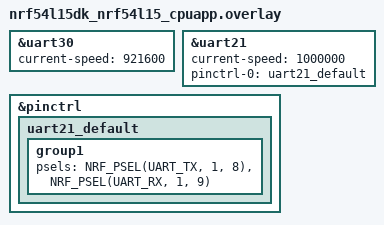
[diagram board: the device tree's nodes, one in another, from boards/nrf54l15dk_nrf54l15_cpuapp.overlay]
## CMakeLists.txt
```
cmake_minimum_required(VERSION 3.20.0)

find_package(Zephyr REQUIRED HINTS $ENV{ZEPHYR_BASE})
project(cs_multi_initiator)

target_sources(app PRIVATE
	src/main.c
	src/cs_config.c
	src/beacon.c
	src/pairing.c
	src/cs_ranging.c
	src/if.c
	src/manager.c
)

target_include_directories(app PRIVATE src)
```

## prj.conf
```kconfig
# ── Base Bluetooth ──
CONFIG_BT=y
CONFIG_BT_CENTRAL=y
CONFIG_BT_DEVICE_NAME="CS Initiator"
# Must be >= MAX_BEACONS (beacon.h)
CONFIG_BT_MAX_CONN=5
# CRITICAL: even in non-bonding (BT_BONDABLE=n), each encrypted connection
# occupies a slot of the bt_keys pool (key_pool[CONFIG_BT_MAX_PAIRED]) for the
# whole session — the session LTK lives there. Zephyr default = 1: from the 2nd
# beacon on, bt_conn_set_security -> bt_keys_get_addr -> pool full (the single
# slot belongs to the connected beacon, so "in use", impossible to purge) ->
# -ENOMEM (-12) in a loop. parnav_cs had this line.
CONFIG_BT_MAX_PAIRED=5

# ── Security (BT_SECURITY_L2, Just Works) ──
CONFIG_BT_SMP=y
# No bonding: without CONFIG_BT_SETTINGS the keys do not survive a reboot, and
# stale RAM bonds break re-securing (err 2 PIN_OR_KEY_MISSING) and saturate the
# key pool (-ENOMEM). CS security only requires an encrypted link: per-session
# pairing, no storage.
CONFIG_BT_BONDABLE=n

# ── NCS scan (UUID filter + auto connect) ──
CONFIG_BT_SCAN=y
CONFIG_BT_SCAN_FILTER_ENABLE=y
CONFIG_BT_SCAN_UUID_CNT=1

# ── GATT client + service discovery (RAS) ──
CONFIG_BT_GATT_CLIENT=y
CONFIG_BT_GATT_DM=y

# ── Channel Sounding ──
CONFIG_BT_CHANNEL_SOUNDING=y
# One CS context per connection at the controller level: without it (default =
# 1), the CS setup of the 2nd reflector fails for lack of resources
CONFIG_BT_CTLR_SDC_CS_COUNT=5
# Duration RESERVED by the SDC in the timeline for each CS event (default =
# 5000 us). Must be >= max_subevent_len (4500 us in cs_config.c), otherwise
# HCI 0x12 at Set Procedure Parameters.
# ⚠ This is a scheduling RESERVATION: 16000 inflated the footprint of each CS
# slot -> the SDC could not find a placement below ~50-60 ms interval (0x0c)
# and deferred the 1st subevent (~700 ms startup). 5000 = 4500 + margin, sticks
# to the real airtime (~10 ms of useful measurement).
CONFIG_BT_CTLR_SDC_CS_EVENT_LEN_DEFAULT=5000

# ── Compaction of the central scheduling (THE ~700 ms bottleneck) ──
# When BT_CTLR_CHANNEL_SOUNDING=y, the SDC by DEFAULT spaces the ACL anchors of
# the central connections by 90000 us (90 ms!) to fit a CS event behind each
# ACL. With 2 links at 60/77.5 ms interval, this 90 ms grid is untenable: the
# SDC defers the 1st CS subevent until it finds a slot (~10-13 connection
# events) and refuses short intervals. We resize it to our real footprints:
#   ACL (3750) + CS event (5000) + margin ≈ 15000 us per link.
# 2 links x 15 ms = 30 ms -> connection interval 24 (30 ms).
# ⚠ TESTED 10000/interval 16: systematic 0x3 abort on both beacons — 1250 us of
#   margin per slot is insufficient (ACL retransmissions, slippage). 15000
#   validated: startup 340 ms, fetch 130-180 ms, 0 abort. Possible intermediate
#   step to validate: 12500 + interval 20 (25 ms).
CONFIG_BT_CTLR_SDC_CENTRAL_ACL_EVENT_SPACING_DEFAULT=15000
# ACL reservation per link: 7500 us by default, brought down to 3750. The event
# extension (CONFIG_BT_CTLR_SDC_CONN_EVENT_EXTEND_DEFAULT=y by default)
# opportunistically lengthens the event when data remains (RAS fetch) and there
# is no conflict: GATT throughput does not collapse.
CONFIG_BT_CTLR_SDC_MAX_CONN_EVENT_LEN_DEFAULT=3750
# One host reassembly buffer per active CS connection (key = conn_handle, freed
# only at disconnection or at the end of a procedure). Default = 1: a residual
# buffer from an aborted procedure on one link can starve the other link. Align
# on MAX_BEACONS (beacon.h) — CRITICAL in free-running (max_procedure_count=0):
# the N links produce procedures in parallel permanently. 5 = CONFIG_BT_MAX_CONN
# (covers all profiles).
CONFIG_BT_CHANNEL_SOUNDING_REASSEMBLY_BUFFER_CNT=5
# Lets CS and ACL use different PHYs (present in the validated single-beacon
# sample)
CONFIG_BT_TRANSMIT_POWER_CONTROL=y

# ── Ranging Service: client (Ranging REQuestor) ──
CONFIG_BT_RAS=y
CONFIG_BT_RAS_RREQ=y

# ── MTU/ACL: fast transfer of the ranging data ──
CONFIG_BT_L2CAP_TX_MTU=247
CONFIG_BT_BUF_ACL_TX_SIZE=251
CONFIG_BT_BUF_ACL_RX_SIZE=251
CONFIG_BT_ATT_PREPARE_COUNT=2

# ── Floats (atan2f, regression) ──
CONFIG_FPU=y
# Several threads use the FPU (ranging in main + display_thread which logs
# floats): without FPU_SHARING the FPU registers are corrupted on a context
# switch
CONFIG_FPU_SHARING=y
# Formatting of the %f in LOG_INF (otherwise corrupted output)
CONFIG_CBPRINTF_FP_SUPPORT=y

# ── Misc ──
CONFIG_DK_LIBRARY=y
CONFIG_SERIAL=y
CONFIG_LOG=y
CONFIG_MAIN_STACK_SIZE=4096
CONFIG_SYSTEM_WORKQUEUE_STACK_SIZE=4096

# ── RTT: enlarged buffer so the boot logs are not lost before the JLink
#    terminal attaches (default = 1 KB, skip mode) ──
CONFIG_USE_SEGGER_RTT=y
CONFIG_LOG_BACKEND_RTT=y
CONFIG_SEGGER_RTT_BUFFER_SIZE_UP=4096
CONFIG_UART_INTERRUPT_DRIVEN=y
```

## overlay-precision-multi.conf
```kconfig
# CONF_DOCKING_PRECISION / CONF_INDOOR_PRECISION profiles with CS_NUM_REFLECTORS=2
# Subevent 8000 us -> CS reservation 8500; grid:
#   SPACING >= ACL 3750 + CS 8500 + guard >= 3000  -> 20000
#   interval = 2 x 20000 = 40 ms (CS_CONN_INTERVAL_UNITS=32 in the profile)
CONFIG_BT_CTLR_SDC_CS_EVENT_LEN_DEFAULT=8500
CONFIG_BT_CTLR_SDC_CENTRAL_ACL_EVENT_SPACING_DEFAULT=20000
# On the REFLECTORS side: mirror CS_EVENT_LEN_DEFAULT=8500.
```

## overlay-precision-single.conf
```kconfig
# CONF_DOCKING_PRECISION / CONF_INDOOR_PRECISION profiles with CS_NUM_REFLECTORS=1
CONFIG_BT_CTLR_SDC_CS_EVENT_LEN_DEFAULT=8500
# A single central link: SPACING has no effect, left at the default.
# On the REFLECTOR side: mirror CS_EVENT_LEN_DEFAULT=8500.
```

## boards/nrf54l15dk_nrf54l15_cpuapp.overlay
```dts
/* ── Initiator UARTs ────────────────────────────────────────────────────────
 * DK mapping (J-Link OB):
 *   uart20  P1.04/P1.05 -> VCOM (Serial Port 1): Zephyr console/logs
 *   uart30  P0.00/P0.01 -> VCOM (Serial Port 0): OUR data+commands channel
 *   uart21  P1.08/P1.09 -> extension header (NO VCOM): drone link
 * if.c selects uart30 (bench PC) or uart21 (drone-embedded) via
 * IF_UART_ON_VCOM in if.c. */

/* 1 Mbaud on the data channel: the continuous IQ dump (IQL/IQP) drops from
 * ~30-60 ms to ~4-7 ms per procedure. Both UARTs set to the same rate to cover
 * if.c's two targets (uart30 = bench-PC VCOM; uart21 = drone link). NB: at
 * 1 Mbaud the DK's J-Link OB may truncate depending on its firmware version;
 * if the IQ lines are corrupt on the VCOM, drop uart30 back to 921600. */
&uart30 {
    status = "okay";
    current-speed = <921600>;
};

&uart21 {
    status = "okay";
    current-speed = <1000000>;
    pinctrl-0 = <&uart21_default>;
    pinctrl-names = "default";
};

&pinctrl {
    uart21_default: uart21_default {
        group1 {
            psels = <NRF_PSEL(UART_TX, 1, 8)>, <NRF_PSEL(UART_RX, 1, 9)>;
        };
    };
};
```

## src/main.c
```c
/*
 * Copyright (c) 2024 Nordic Semiconductor ASA
 * SPDX-License-Identifier: LicenseRef-Nordic-5-Clause
 */

#include <zephyr/kernel.h>
#include <zephyr/bluetooth/bluetooth.h>
#include <zephyr/bluetooth/conn.h>
#include <bluetooth/scan.h>
#include "beacon.h"
#include "pairing.h"
#include "cs_ranging.h"
#include "if.h"
#include "manager.h"
#include "cs_config.h"

#include <dk_buttons_and_leds.h>

#include <zephyr/logging/log.h>
LOG_MODULE_REGISTER(app_main, LOG_LEVEL_INF);

/* Ranging Service UUID 0x185B — advertised by the reflector firmware */
static struct bt_uuid_16 ranging_svc_uuid = BT_UUID_INIT_16(0x185B);
#define BT_UUID_RANGING_SERVICE ((struct bt_uuid *)&ranging_svc_uuid)

#define CON_STATUS_LED DK_LED1

/* Declared in pairing.c */
extern void security_changed_cb(struct bt_conn *conn, bt_security_t level,
				enum bt_security_err err);

/* ── Connection callbacks ────────────────────────────────────────────────── */

static void connected_cb(struct bt_conn *conn, uint8_t err)
{
	char addr[BT_ADDR_LE_STR_LEN];

	bt_addr_le_to_str(bt_conn_get_dst(conn), addr, sizeof(addr));
	LOG_INF("Connected: %s (err 0x%02X)", addr, err);

	if (err) {
		/* No unref here: the application has not taken a reference yet,
		 * the scan module manages its own. */
		return;
	}

	/* Reject duplicate connection to already-connected beacon */
	const bt_addr_le_t *addr_le = bt_conn_get_dst(conn);

	/* Whitelist manager: rejects any address off the list when the
	 * whitelist is active (WL:ON). Always OK when disabled. */
	if (!manager_addr_allowed(addr_le)) {
		LOG_WRN("Connection rejected (not whitelisted): %s", addr);
		bt_conn_disconnect(conn, BT_HCI_ERR_REMOTE_USER_TERM_CONN);
		return;
	}

	k_mutex_lock(&beacons_mutex, K_FOREVER);
	for (int i = 0; i < MAX_BEACONS; i++) {
		if (beacons[i].active && beacons[i].conn != NULL &&
		    bt_addr_le_cmp(bt_conn_get_dst(beacons[i].conn), addr_le) == 0) {
			k_mutex_unlock(&beacons_mutex);
			LOG_WRN("Duplicate connection rejected");
			bt_conn_disconnect(conn, BT_HCI_ERR_REMOTE_USER_TERM_CONN);
			return;
		}
	}
	k_mutex_unlock(&beacons_mutex);

	struct bt_conn *ref = bt_conn_ref(conn);

	if (k_msgq_put(&new_conn_queue, &ref, K_NO_WAIT) != 0) {
		LOG_ERR("Queue full, disconnecting");
		bt_conn_unref(ref);
		bt_conn_disconnect(conn, BT_HCI_ERR_REMOTE_USER_TERM_CONN);
		return;
	}

	dk_set_led_on(CON_STATUS_LED);
}

static void disconnected_cb(struct bt_conn *conn, uint8_t reason)
{
	char addr[BT_ADDR_LE_STR_LEN];

	bt_addr_le_to_str(bt_conn_get_dst(conn), addr, sizeof(addr));
	LOG_INF("Disconnected: %s (reason 0x%02X)", addr, reason);

	/* Release-once: the unref is done only if THIS call freed the slot.
	 * Avoids the double-unref (refcount underflow) racing with the pairing
	 * thread's error path. */
	if (free_beacon(conn)) {
		bt_conn_unref(conn);
	}

	dk_set_led_off(CON_STATUS_LED);
}

static bool le_param_req(struct bt_conn *conn, struct bt_le_conn_param *param)
{
	return false;
}

BT_CONN_CB_DEFINE(conn_cb) = {
	.connected      = connected_cb,
	.disconnected   = disconnected_cb,
	.le_param_req   = le_param_req,
	.security_changed = security_changed_cb,
};

/* ── Scan ────────────────────────────────────────────────────────────────── */

static void scan_filter_match(struct bt_scan_device_info *device_info,
			      struct bt_scan_filter_match *filter_match, bool connectable)
{
	char addr[BT_ADDR_LE_STR_LEN];

	bt_addr_le_to_str(device_info->recv_info->addr, addr, sizeof(addr));
	LOG_INF("Found beacon: %s", addr);
}

static void scan_connecting_error(struct bt_scan_device_info *device_info)
{
	LOG_WRN("Connection attempt failed");
}

static void scan_connecting(struct bt_scan_device_info *device_info, struct bt_conn *conn)
{
	LOG_INF("Connecting...");
}

BT_SCAN_CB_INIT(scan_cb, scan_filter_match, NULL, scan_connecting_error, scan_connecting);

static int scan_init(void)
{
	int err;
	/* Initial connection parameters = cs_cp_active (single source in
	 * cs_config.h/.c). No static init possible from a variable: we point
	 * the scan directly at the global struct. */
	struct bt_scan_init_param param = {
		.scan_param = NULL,
		.conn_param = &cs_cp_active,
		.connect_if_match = 1,
	};

	bt_scan_init(&param);
	bt_scan_cb_register(&scan_cb);

	err = bt_scan_filter_add(BT_SCAN_FILTER_TYPE_UUID, BT_UUID_RANGING_SERVICE);
	if (err) {
		LOG_ERR("Filter add failed (err %d)", err);
		return err;
	}

	err = bt_scan_filter_enable(BT_SCAN_UUID_FILTER, false);
	if (err) {
		LOG_ERR("Filter enable failed (err %d)", err);
		return err;
	}

	return 0;
}

/* ── 1 Hz display ────────────────────────────────────────────────────────── */

/* 2048: the cbprintf packaging of the %f in LOG_INF happens in the caller
 * context — 512 bytes overflowed the stack (random hard fault). */
#define DISPLAY_STACK_SIZE 2048
#define DISPLAY_PRIORITY   7
K_THREAD_STACK_DEFINE(display_stack, DISPLAY_STACK_SIZE);
static struct k_thread display_thread_data;

static void display_thread(void *p1, void *p2, void *p3)
{
	char addr_str[BT_ADDR_LE_STR_LEN];

	while (true) {
		k_sleep(K_MSEC(1000));

		k_mutex_lock(&beacons_mutex, K_FOREVER);
		int n = 0;

		for (int i = 0; i < MAX_BEACONS; i++) {
			if (!beacons[i].active) {
				continue;
			}
			n++;
			bt_addr_le_to_str(&beacons[i].addr, addr_str, sizeof(addr_str));
			LOG_INF("[%d] %s  %s", i, addr_str,
				beacons[i].cs_ready ? "ranging" : "setup");
		}

		if (n == 0) {
			LOG_INF("No beacons connected");
		}

		k_mutex_unlock(&beacons_mutex);
	}
}

/* ── Main ────────────────────────────────────────────────────────────────── */

int main(void)
{
	int err;

	LOG_INF("Starting multi-beacon initiator");

	dk_leds_init();

	if (if_initialisation()) {
		LOG_ERR("UART init failed");
	}

	/* Application manager: UART commands (IQON/IQOFF, whitelist, chmap),
	 * connection filtering by whitelist, channel-map hot-swap staging. */
	manager_init();
	if_set_line_cb(manager_uart_line);

	err = bt_enable(NULL);
	if (err) {
		LOG_ERR("Bluetooth init failed (err %d)", err);
		return 0;
	}

	err = scan_init();
	if (err) {
		LOG_ERR("Scan init failed (err %d)", err);
		return 0;
	}

	k_thread_create(&pairing_thread_data, pairing_stack, PAIRING_STACK_SIZE,
			(k_thread_entry_t)pairing_n_bluetooth, NULL, NULL, NULL,
			PAIRING_PRIORITY, 0, K_NO_WAIT);

	k_thread_create(&display_thread_data, display_stack, DISPLAY_STACK_SIZE,
			display_thread, NULL, NULL, NULL,
			DISPLAY_PRIORITY, 0, K_NO_WAIT);

	/* ── Blocking init: do not continue until the MAX_BEACONS reflectors
	 *    are connected and secured ──────────────────────────────────── */
	LOG_INF("Waiting for %d reflectors...", MAX_BEACONS);
	err = pairing_wait_all_connected(K_FOREVER);
	if (err) {
		LOG_ERR("Wait for reflectors failed (err %d)", err);
		return 0;
	}
	LOG_INF("All %d reflectors connected — starting application", MAX_BEACONS);

	/* ── CONTINUOUS MEASUREMENT (free-running) ───────────────────────────────
	 * Each beacon's CS procedures are armed ONCE (max_procedure_count = 0):
	 * the controller then repeats them every procedure_interval without a new
	 * LL handshake — the ~495 ms startup (≈ 11 x connection interval) is paid
	 * only at arming, never again per measurement. The old one-shot pipeline
	 * paid this startup on EVERY measurement (3-beacon cycle ≈ 1485 ms); here
	 * the loop only collects the pairs (local steps + peer RAS) as they come:
	 * cycle ≈ procedure period (~180 ms in drone N=3).
	 * NOTE: no bt_conn_ref during the measurement (a disconnect mid-cycle is
	 * unprotected) — OK on the bench, to harden for production. */
	cs_ranging_init();

	bool armed[MAX_BEACONS] = { false };

	while (true) {
		bool enable_failed = false;
		bool any_collected = false;
		int64_t t_cycle = k_uptime_get();

		/* Simple round-robin over all beacons (the scheduler was removed:
		 * in free-running each link measures continuously, the order has
		 * no effect on the rate). */
		for (int i = 0; i < MAX_BEACONS; i++) {
			bool ready;

			k_mutex_lock(&beacons_mutex, K_FOREVER);
			ready = beacons[i].active && beacons[i].cs_ready &&
				beacons[i].conn != NULL;
			k_mutex_unlock(&beacons_mutex);

			if (!ready) {
				/* Disconnected: the controller has stopped its
				 * procedures, we will re-arm on return. */
				armed[i] = false;
				continue;
			}

			/* Not armed yet (startup, reconnection, or failure on
			 * the previous round): arm and move on — the first
			 * measurement arrives after the LL startup, while the
			 * loop collects the other beacons. */
			if (!armed[i]) {
				armed[i] = (cs_enable_beacon(i) == 0);
				enable_failed |= !armed[i];
				continue;
			}

			/* Collect the next paired measurement + timestamped IQ
			 * dump (IQL/IQP). No distance: computed off-board
			 * (Python) from the IQ lines. */
			bool rearmed = true;
			int rc = cs_collect_beacon(i, &rearmed);

			any_collected = true;
			if (!rearmed) {
				armed[i] = false;
				enable_failed = true;
			}
			if (rc != 0) {
				LOG_WRN("Beacon[%d] ranging failed", i);
			}
		}

		LOG_INF("cycle: %lld ms", k_uptime_get() - t_cycle);

		/* Backoff if nothing was collected this round (all disconnected
		 * or just armed): avoids a busy spin. In nominal operation the
		 * loop is paced by the collection semaphores (cs_collect_beacon). */
		if (enable_failed || !any_collected) {
			k_sleep(K_MSEC(50));
		}
	}

	return 0;
}
```

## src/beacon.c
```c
#include "beacon.h"

#include <zephyr/logging/log.h>
LOG_MODULE_DECLARE(app_main, LOG_LEVEL_INF);

struct beacon_state beacons[MAX_BEACONS];
K_MUTEX_DEFINE(beacons_mutex);
K_MSGQ_DEFINE(new_conn_queue, sizeof(struct bt_conn *), MAX_BEACONS, sizeof(void *));

struct beacon_state *find_beacon(struct bt_conn *conn)
{
	for (int i = 0; i < MAX_BEACONS; i++) {
		if (beacons[i].active && beacons[i].conn == conn) {
			return &beacons[i];
		}
	}
	return NULL;
}

struct beacon_state *alloc_beacon(struct bt_conn *conn)
{
	k_mutex_lock(&beacons_mutex, K_FOREVER);
	for (int i = 0; i < MAX_BEACONS; i++) {
		if (!beacons[i].active) {
			beacons[i].conn     = conn;
			beacons[i].active   = true;
			beacons[i].cs_ready = false;
			bt_addr_le_copy(&beacons[i].addr, bt_conn_get_dst(conn));
			k_mutex_unlock(&beacons_mutex);
			return &beacons[i];
		}
	}
	k_mutex_unlock(&beacons_mutex);
	return NULL;
}

bool free_beacon(struct bt_conn *conn)
{
	bool released = false;

	if (conn == NULL) {
		return false;
	}

	k_mutex_lock(&beacons_mutex, K_FOREVER);
	for (int i = 0; i < MAX_BEACONS; i++) {
		if (beacons[i].conn == conn) {
			beacons[i].active        = false;
			beacons[i].conn          = NULL;
			beacons[i].cs_ready      = false;
			released = true;
			break;
		}
	}
	k_mutex_unlock(&beacons_mutex);

	return released;
}

void decalage(void)
{
	k_mutex_lock(&beacons_mutex, K_FOREVER);
	for (int left = 0; left < MAX_BEACONS; left++) {
		if (beacons[left].active) {
			continue;
		}
		/* free slot found: look for the next active one to the right */
		for (int right = left + 1; right < MAX_BEACONS; right++) {
			if (beacons[right].active) {
				beacons[left]         = beacons[right];
				beacons[right].active = false;
				beacons[right].conn   = NULL;
				break;
			}
		}
	}
	k_mutex_unlock(&beacons_mutex);
}
```

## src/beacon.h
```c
#ifndef BEACON_H
#define BEACON_H

#include <zephyr/kernel.h>
#include <zephyr/bluetooth/conn.h>

#include "cs_config.h"

/* Sized by the application profile (cs_config.h) */
#define MAX_BEACONS CS_MAX_BEACONS

struct beacon_state {
	struct bt_conn *conn;
	bt_addr_le_t   addr;
	bool           active;
	/* Channel Sounding */
	bool           cs_ready;     /* CS setup done, ranging possible */
	uint8_t        cs_config_id; /* CS config id returned by the controller */
};

extern struct beacon_state beacons[MAX_BEACONS];
extern struct k_mutex      beacons_mutex;
extern struct k_msgq       new_conn_queue;

struct beacon_state *find_beacon(struct bt_conn *conn);
struct beacon_state *alloc_beacon(struct bt_conn *conn);
/* Frees the slot associated with conn. Returns true ONLY for the caller that
 * actually freed the slot: it is the one that must call bt_conn_unref.
 * Guarantees exactly one unref even if disconnected_cb and the pairing error
 * path run concurrently. */
bool                 free_beacon(struct bt_conn *conn);
void                 decalage(void);

#endif /* BEACON_H */
```

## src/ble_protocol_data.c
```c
#include "ble_protocol_data.h"
#include "if.h"
#include <string.h>
#include <zephyr/logging/log.h>
#define MAX_NUM_IQ_SAMPLES 148

LOG_MODULE_DECLARE(app_main, LOG_LEVEL_INF);

#define MAX_PACKET_SIZE (2 + 15 * MAX_NUM_IQ_SAMPLES + 2)  /* 15 octets/sample : beacon_idx + channel + antenna + 4xIQ + float */

static uint8_t buffer[MAX_PACKET_SIZE];

void ble_protocol_data_send_batch(const struct iq_sample_packet *samples,
                                  uint16_t count) {
    if (count == 0) {
        return;
    }

    /* Avec la config CS validée (mode 2+1, chmap repetition 5), une
     * procédure peut produire plus de MAX_NUM_IQ_SAMPLES échantillons :
     * on découpe en plusieurs trames au lieu de jeter le lot entier
     * (l'ancien code faisait `return` silencieusement). */
    while (count > MAX_NUM_IQ_SAMPLES) {
        ble_protocol_data_send_batch(samples, MAX_NUM_IQ_SAMPLES);
        samples += MAX_NUM_IQ_SAMPLES;
        count -= MAX_NUM_IQ_SAMPLES;
    }

    uint16_t offset = 0;

    // Header: 'R~'
    const uint8_t header[] = {0x52, 0x7E};
    memcpy(&buffer[offset], header, sizeof(header));
    offset += sizeof(header);

    // IQ Sample Payload
    for (uint16_t i = 0; i < count; i++) {
        const struct iq_sample_packet *s = &samples[i];

        memcpy(&buffer[offset], &s->beacon_idx, sizeof(s->beacon_idx));
        offset += sizeof(s->beacon_idx);
        memcpy(&buffer[offset], &s->channel, sizeof(s->channel));
        offset += sizeof(s->channel);
        memcpy(&buffer[offset], &s->antenna_index, sizeof(s->antenna_index));
        offset += sizeof(s->antenna_index);

        memcpy(&buffer[offset], &s->local_i, sizeof(int16_t));
        offset += sizeof(int16_t);
        memcpy(&buffer[offset], &s->local_q, sizeof(int16_t));
        offset += sizeof(int16_t);
        memcpy(&buffer[offset], &s->peer_i, sizeof(int16_t));
        offset += sizeof(int16_t);
        memcpy(&buffer[offset], &s->peer_q, sizeof(int16_t));
        offset += sizeof(int16_t);

        // New: Serialize phase_distance_m
        memcpy(&buffer[offset], &s->phase_distance_m, sizeof(float));
        offset += sizeof(float);
    }

    // Footer: '~E'
    const uint8_t footer[] = {0x7E, 0x45};
    memcpy(&buffer[offset], footer, sizeof(footer));
    offset += sizeof(footer);

    LOG_INF("Serialisation done, buffer length = %d", offset);
    if_send(buffer, offset);

}
```

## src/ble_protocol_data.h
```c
#ifndef BLE_PROTOCOL_DATA_H_
#define BLE_PROTOCOL_DATA_H_

#include <stdint.h>

// #define MAX_NUM_IQ_SAMPLES (256 * CONFIG_BT_RAS_MAX_ANTENNA_PATHS)

struct iq_sample_packet {
	uint8_t beacon_idx;   /* identifie le réflecteur source de la mesure */
	uint8_t channel;
	uint8_t antenna_index;
	int16_t local_i;
	int16_t local_q;
	int16_t peer_i;
	int16_t peer_q;
	float phase_distance_m;
};

void ble_protocol_data_send_batch(const struct iq_sample_packet *samples, uint16_t count);

#endif /* BLE_PROTOCOL_DATA_H_ */
```

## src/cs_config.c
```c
#include "cs_config.h"

/* ── CONSISTENCY GUARDS prj.conf <-> profile (see cs_config.h) ─────────────
 * Refuse compilation if the SDC timeline reservations do not cover the selected
 * profile — this is exactly the class of errors that produced the historical
 * 700 ms startup and 0x3 aborts. */
BUILD_ASSERT(CONFIG_BT_CTLR_SDC_CS_EVENT_LEN_DEFAULT >= CS_SUBEVENT_LEN_US,
	     "CS_EVENT_LEN_DEFAULT < max_subevent_len: Procedure Params rejected (0x12). "
	     "Adapt the prj.conf overlay to the profile.");
BUILD_ASSERT(CS_NUM_BEACONS >= 1 && CS_NUM_BEACONS <= 5,
	     "CS_NUM_BEACONS must be between 1 and 5.");
BUILD_ASSERT(CONFIG_BT_MAX_CONN >= CS_NUM_BEACONS,
	     "CONFIG_BT_MAX_CONN < CS_NUM_BEACONS (prj.conf).");
BUILD_ASSERT(CONFIG_BT_CTLR_SDC_CS_COUNT >= CS_NUM_BEACONS,
	     "CONFIG_BT_CTLR_SDC_CS_COUNT < CS_NUM_BEACONS: not enough concurrent "
	     "CS procedures for the pipeline (prj.conf).");
#if CS_MAX_BEACONS > 1
BUILD_ASSERT(CONFIG_BT_CTLR_SDC_CENTRAL_ACL_EVENT_SPACING_DEFAULT >=
	     CONFIG_BT_CTLR_SDC_MAX_CONN_EVENT_LEN_DEFAULT +
	     CONFIG_BT_CTLR_SDC_CS_EVENT_LEN_DEFAULT + 3000,
	     "SPACING too small for ACL + CS event + 3 ms guard: structural 0x3 "
	     "aborts guaranteed (20 ms/10000 measurement failure).");
BUILD_ASSERT(CS_CONN_INTERVAL_UNITS * 1250 >=
	     CS_MAX_BEACONS * CONFIG_BT_CTLR_SDC_CENTRAL_ACL_EVENT_SPACING_DEFAULT,
	     "Connection interval < N_links x SPACING: the grid does not fit "
	     "(Procedure Enable 0x0C or deferred startup).");
#endif

struct bt_le_cs_set_default_settings_param cs_settings = {
    .enable_initiator_role     = true,
    .enable_reflector_role     = false,
    .cs_sync_antenna_selection = BT_LE_CS_ANTENNA_SELECTION_OPT_ONE,
    .max_tx_power              = CS_MAX_TX_POWER, /* profile: max for range,
                                                   * reduced in docking (anti-
                                                   * saturation < a few meters) */
};

struct bt_le_cs_create_config_params cs_create_config = {
    .id                     = 0,
    .mode                   = CS_MODE, /* profile: PBR + RTT (drone, ambiguity resolution beyond the non-ambiguous range) or pure PBR (short-range precision) */
    .min_main_mode_steps    = 2,
    .max_main_mode_steps    = CS_MAIN_STEPS_MAX, /* more steps/subevent = channels packed tighter (precision profiles) vs short subevents (drone profiles) */
    .main_mode_repetition   = 1,
    .mode_0_steps           = CS_MODE0_STEPS,    /* 3 in precision: better frequency-offset estimation */
    .role                   = BT_CONN_LE_CS_ROLE_INITIATOR,
    .rtt_type               = CS_RTT_TYPE, /* 32-bit sounding (drone): fine timestamping + NADM; AA_ONLY (pure PBR) */
    .cs_sync_phy            = CS_SYNC_PHY, /* 2M_2BT only refines the CS_SYNC (RTT), not the PBR phase */
    .channel_map_repetition = CS_CHMAP_REPETITION, /* 2 in docking N<=2: each channel sounded 2x (slow and near target, ODS note) */
    .channel_selection_type = CS_CHSEL_TYPE, /* 3C+X in fast drone: time-frequency decorrelation (ODS note) */
    .ch3c_shape             = CS_CH3C_SHAPE,
    .ch3c_jump              = 2,
    .cs_enhancements_1      = 0,
};

struct bt_le_cs_set_procedure_parameters_param cs_proc_params = {
    .config_id              = 0, /* updated at runtime in do_set_procedure_params() */
    .max_procedure_len      = CS_PROC_LEN_UNITS, /* x0.625 ms. Short window = easy placement (drone); wide for ~72 channels (precision) */
    /* Per-link sampling period = interval x connection interval (unit:
     * connection events). Drone N=3: 4 x 45 ms = 180 ms/beacon. */
    .min_procedure_interval = 4,
    .max_procedure_interval = 4,
    /* 0 = FREE-RUNNING: the controller repeats the procedures every
     * procedure_interval until disable. The LL handshake (~11 events x
     * interval ≈ 495 ms) is paid ONLY ONCE at arming, never again per
     * measurement — it was what capped the rate in one-shot
     * (max_procedure_count=1: 3-beacon cycle ≈ 1485 ms observed). */
    .max_procedure_count    = 0,
    .min_subevent_len       = CS_SUBEVENT_LEN_US,
    .max_subevent_len       = CS_SUBEVENT_LEN_US, /* ⚠ coupled to CONFIG_BT_CTLR_SDC_CS_EVENT_LEN_DEFAULT (BUILD_ASSERT above) */
    .tone_antenna_config_selection = BT_LE_CS_TONE_ANTENNA_CONFIGURATION_A1_B1,
    .phy                    = BT_LE_CS_PROCEDURE_PHY_2M,
    .tx_power_delta         = 0x80,
    .preferred_peer_antenna = 1,
    .snr_control_initiator  = BT_LE_CS_SNR_CONTROL_NOT_USED,
    .snr_control_reflector  = BT_LE_CS_SNR_CONTROL_NOT_USED,
};

struct bt_le_conn_param cs_cp_active = {
    /* FIXED interval (min == max). CS startup ≈ ~11 events x interval
     * (LL_CS_REQ/RSP/IND + SDC margin: the NUMBER of events is not
     * configurable, only their DURATION is). In multi: interval =
     * CS_MAX_BEACONS x SPACING (deterministic grid, cf. BUILD_ASSERT).
     * In single: floor = ACL + CS event + margin, SPACING does not apply
     * (a single central connection).
     * VALIDATED multi-drone 24/15000: startup 340 ms, 0 abort.
     * FAILURE 16/10000: 1250 us guard too tight → structural 0x3 abort. */
    .interval_min = CS_CONN_INTERVAL_UNITS,
    .interval_max = CS_CONN_INTERVAL_UNITS,
    .latency      = 0,
    .timeout      = 3200,
};
```

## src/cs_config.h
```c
#ifndef CS_CONFIG_H_
#define CS_CONFIG_H_

/*io pin trigger par une interruption pour chaque cs ranging et envoyer a la sentiboard pour avoir un timestamp */

#include <zephyr/bluetooth/bluetooth.h>
#include <zephyr/bluetooth/conn.h>
#include <zephyr/bluetooth/cs.h>

/* ═══════════════════════════════════════════════════════════════════════════
 * 1) FAMILLE APPLICATIVE — décommenter EXACTEMENT UNE.
 * 2) CS_NUM_BEACONS — nombre de réflecteurs (1 à 5). TOUT le timing et le
 *    dimensionnement en découlent automatiquement (intervalle = N × créneau,
 *    buffers, scheduler) ; garde-fous BUILD_ASSERT dans cs_config.c.
 *
 * Overlays prj.conf par famille (réservations SDC, indépendantes de N) :
 *   DRONE_FAST_OUTDOOR : aucun (prj.conf de base : CS_EVENT 5000/SPACING 15000)
 *   BOAT_DOCKING / DRONE_INDOOR, N>=2 : overlay-precision-multi.conf
 *   BOAT_DOCKING / DRONE_INDOOR, N==1 : overlay-precision-single.conf
 * Rappel : reflasher aussi les réflecteurs si CS_EVENT_LEN change de famille.
 * Référence des paramètres : doc_optimised_parameters.ods (renvois Vol 6 H).
 * ═══════════════════════════════════════════════════════════════════════════ */
//#define CONF_DRONE_FAST_OUTDOOR   /*drone extérieur rapide */
#define CONF_BOAT_DOCKING /*   accostage bateau, précision courte portée */
//- #define CONF_DRONE_INDOOR    /* drone lent intérieur, multipath dense */

#define CS_NUM_BEACONS 2          /* 1..5 */

/* Mode de récupération des ranging data pair : 1 = RAS temps réel (fetch ~0,
 * pas de rétention), 0 = on-demand (fallback validé). Voir itération 3. */
#define CS_RAS_REALTIME 1

/* ─────────────────────────────────────────────────────────────────────────
 * FAMILLE : DRONE EXTÉRIEUR RAPIDE
 * Priorité : cadence + robustesse au mouvement. Peu de canaux (airtime et
 * data minimaux), créneau de 15 ms/lien, RTT sounding (levée d'ambiguïté
 * fiable au-delà de 50 m). NOTE capacités SDC : 3C/X, 2M_2BT, sounding et
 * NADM documentés dans l'ODS ne sont PAS supportés par le SoftDevice
 * Controller (Create Config 0x11 constaté) — voir le bloc CS_RTT_TYPE.
 * ───────────────────────────────────────────────────────────────────────── */
#if defined(CONF_DRONE_FAST_OUTDOOR)
#define CS_CHANNEL_THINNING     3     /* ~24 canaux, non-ambigu PBR 50 m */
#define CS_SUBEVENT_LEN_US      4500
#define CS_PROC_LEN_UNITS       40    /* 25 ms : fenêtre courte, placement facile */
#define CS_MODE0_STEPS          2
#define CS_MAIN_STEPS_MAX       6
#define CS_MODE                 BT_CONN_LE_CS_MAIN_MODE_2_SUB_MODE_1 /*tester sans submode
/* ⚠ CAPACITÉS SDC (table nrfxlib, vérifiée sur cible — Create Config 0x11
 * sinon) : sounding sequence, CSA #3C, 2M_2BT et NADM NON SUPPORTÉS par le
 * SoftDevice Controller. Le levier de datation RTT DISPONIBLE est la
 * random payload (32/64/96/128 bits, supportée) : corrélation affinée vs
 * AA-only, même rôle que la sounding d'après la spec (§2, Vol 6 Part H).
 * Fallback validé banc : BT_CONN_LE_CS_RTT_TYPE_AA_ONLY. */
#define CS_RTT_TYPE             BT_CONN_LE_CS_RTT_TYPE_32_BIT_RANDOM
#define CS_SYNC_PHY             BT_CONN_LE_CS_SYNC_2M_PHY      /* 2M_2BT non supporté SDC */
#define CS_CHSEL_TYPE           BT_CONN_LE_CS_CHSEL_TYPE_3B    /* #3C non supporté SDC */
#define CS_CH3C_SHAPE           BT_CONN_LE_CS_CH3C_SHAPE_HAT   /* sans effet en 3B */
#define CS_CHMAP_REPETITION     1
#define CS_MAX_TX_POWER         BT_HCI_OP_LE_CS_MAX_MAX_TX_POWER
#define CS_SPACING_UNITS        12    /* 15 ms/lien = ACL 3750 + CS 5000 + marge */
#define CS_SINGLE_FLOOR_UNITS   12
/* RAM : à 4-5 beacons, buffers réduits (24 canaux → ~30 steps réels). */
#define CS_MAX_STEPS_PER_PROC   (CS_NUM_BEACONS >= 4 ? 48 : 64)
#define CS_SCHED_DEFAULT_REPEAT 1

/* ─────────────────────────────────────────────────────────────────────────
 * FAMILLE : ACCOSTAGE BATEAU (précision, < 30 m, dynamique lente)
 * Tous les canaux = résolution max ; TX 0 dBm (anti-saturation proche) ;
 * cible lente et proche → channel_map_repetition 2 quand la RAM le permet
 * (N<=2, cf. note ODS), sinon moyennage par le scheduler (2 mesures/round).
 * PBR pur (non-ambigu 150 m >> enveloppe) → pas de RTT, chsel 3B (statique).
 * ⚠ N>=4 : thinning 2 imposé (75 m non-ambigu, RAM ~÷2 par beacon).
 * ───────────────────────────────────────────────────────────────────────── */
#elif defined(CONF_BOAT_DOCKING)
#define CS_CHANNEL_THINNING     (CS_NUM_BEACONS >= 3 ? 2 : 1)
#define CS_SUBEVENT_LEN_US      8000
#define CS_PROC_LEN_UNITS       100   /* 62,5 ms : ~72 canaux à écouler */
#define CS_MODE0_STEPS          3
#define CS_MAIN_STEPS_MAX       10
#define CS_MODE                 BT_CONN_LE_CS_MAIN_MODE_2_NO_SUB_MODE
#define CS_RTT_TYPE             BT_CONN_LE_CS_RTT_TYPE_AA_ONLY /* sans objet en PBR pur */
#define CS_SYNC_PHY             BT_CONN_LE_CS_SYNC_2M_PHY
#define CS_CHSEL_TYPE           BT_CONN_LE_CS_CHSEL_TYPE_3B
#define CS_CH3C_SHAPE           BT_CONN_LE_CS_CH3C_SHAPE_HAT   /* inutilisé en 3B */
#define CS_CHMAP_REPETITION     (CS_NUM_BEACONS <= 2 ? 2 : 1)
/* Puissance TX max (EIRP) de TOUTES les transmissions CS. PLAFOND : le
 * contrôleur prend le niveau matériel supporté le plus proche <= cette valeur.
 * Plage HCI -127..+20 dBm ; nRF54L15 : max réel +8 dBm (au-delà = plafonné).
 * BT_HCI_OP_LE_CS_MAX_MAX_TX_POWER (=20) = "prends le maximum matériel".
 * ⚠ Baisser la TX ne réduit PAS le multipath (direct et réflexions atténués du
 *   même rapport) : le 0 dBm ci-dessous est de l'anti-saturation courte portée
 *   (< qq m, un signal trop fort déforme la phase), pas un filtre multipath.
 *   À distance / en extérieur, MONTER la TX pour le SNR.
 * Paliers indicatifs (dBm) :
 *      0    accostage serré < ~3 m (anti-saturation)      <-- valeur actuelle
 *     +4    intérieur / quelques mètres
 *     +8    extérieur, portée max nRF54L15
 *   BT_HCI_OP_LE_CS_MAX_MAX_TX_POWER   laisse le contrôleur prendre son max */
#define CS_MAX_TX_POWER         8    /* dBm */
#define CS_SPACING_UNITS        16    /* 20 ms/lien = ACL 3750 + CS 8500 + marge */
#define CS_SINGLE_FLOOR_UNITS   16
#define CS_MAX_STEPS_PER_PROC   (CS_NUM_BEACONS <= 2 ? 176 : \
                                 (CS_NUM_BEACONS == 3 ? 96 : 64))
#define CS_SCHED_DEFAULT_REPEAT 2

/* ─────────────────────────────────────────────────────────────────────────
 * FAMILLE : DRONE LENT INTÉRIEUR (multipath dense)
 * La diversité fréquentielle est LE remède au multipath : tous les canaux,
 * mode-0 renforcé, TX max (budget NLOS). Cible lente → 3B suffit ; le
 * lissage vient du scheduler (2 mesures/round) + pondération γ côté Python.
 * ⚠ N>=4 : thinning 2 imposé (RAM), à éviter si le multipath est sévère.
 * ───────────────────────────────────────────────────────────────────────── */
#elif defined(CONF_DRONE_INDOOR)
#define CS_CHANNEL_THINNING     (CS_NUM_BEACONS >= 4 ? 2 : 1)
#define CS_SUBEVENT_LEN_US      8000
#define CS_PROC_LEN_UNITS       100
#define CS_MODE0_STEPS          3
#define CS_MAIN_STEPS_MAX       10
#define CS_MODE                 BT_CONN_LE_CS_MAIN_MODE_2_NO_SUB_MODE
#define CS_RTT_TYPE             BT_CONN_LE_CS_RTT_TYPE_AA_ONLY
#define CS_SYNC_PHY             BT_CONN_LE_CS_SYNC_2M_PHY
#define CS_CHSEL_TYPE           BT_CONN_LE_CS_CHSEL_TYPE_3B
#define CS_CH3C_SHAPE           BT_CONN_LE_CS_CH3C_SHAPE_HAT
#define CS_CHMAP_REPETITION     1
#define CS_MAX_TX_POWER         BT_HCI_OP_LE_CS_MAX_MAX_TX_POWER
#define CS_SPACING_UNITS        16
#define CS_SINGLE_FLOOR_UNITS   16
#define CS_MAX_STEPS_PER_PROC   (CS_NUM_BEACONS >= 4 ? 64 : 96)
#define CS_SCHED_DEFAULT_REPEAT 2

#else
#error "cs_config.h : sélectionner exactement une famille CONF_*"
#endif

/* ── Dérivés communs (ne pas éditer) ────────────────────────────────────────
 * Intervalle de connexion : N==1 → plancher single (le quadrillage SPACING ne
 * s'applique qu'entre connexions centrales) ; N>=2 → N × créneau, le SDC
 * espace les ancres ACL de SPACING (déterministe, sans collision).
 * Startup ≈ 11 × intervalle (LL_CS_REQ/RSP/IND + marge SDC, incompressible
 * en nombre), payé UNE FOIS à l'armement en free-running
 *#define CS_CHANNEL_THINNING  (CS_NUM_BEACONS >= 3 ? 2 : 1) (max_procedure_count = 0). La cadence en régime établi vaut ensuite
 * procedure_interval × intervalle de connexion par beacon (∝ N). */
#define CS_MAX_BEACONS          CS_NUM_BEACONS
#define CS_CONN_INTERVAL_UNITS  (CS_NUM_BEACONS == 1 ? CS_SINGLE_FLOOR_UNITS \
                                 : CS_NUM_BEACONS * CS_SPACING_UNITS)
#define CS_ACL_DESYNC_STEP      0  /* précession inutile avec le quadrillage ;
                                    * fallback 6 si aborts 0x3 figés */

extern struct bt_le_cs_set_default_settings_param     cs_settings;
extern struct bt_le_cs_create_config_params           cs_create_config;
extern struct bt_le_cs_set_procedure_parameters_param cs_proc_params;
extern struct bt_le_conn_param                        cs_cp_active;
/* cs_cp_standby SUPPRIMÉ : vestige round-robin actif/veille. Perspective
 * N>=4 (note ODS sur .id/config par réflecteur) : parquer en latency les
 * beacons hors du round courant — non implémenté. */

#endif /* CS_CONFIG_H_ */
```

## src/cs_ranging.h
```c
#ifndef CS_RANGING_H
#define CS_RANGING_H

#include <zephyr/kernel.h>
#include "beacon.h"

/* Full Channel Sounding setup for a freshly secured (L2) beacon: RAS
 * discovery, capabilities, default settings, CS config, CS security, procedure
 * parameters. BLOCKING (internal semaphores).
 * Call from the pairing thread, sequentially.
 * Returns 0 if the beacon is ready for ranging. */
int cs_setup_beacon(struct beacon_state *beacon);

/* Init of the per-beacon measurement states. Call once before the loop. */
void cs_ranging_init(void);

/* FREE-RUNNING (max_procedure_count = 0: the controller repeats the procedures
 * every procedure_interval, the ~495 ms LL handshake is paid only at arming):
 *  - cs_enable_beacon(i)  : ARMS beacon i's procedures, ONCE (and after a
 *                           reconnection). Returns 0 if accepted.
 *  - cs_collect_beacon(i) : waits for the next paired measurement (local steps
 *                           + peer ranging data of the same counter) and emits
 *                           the timestamped IQ dump (IQL/IQP). Returns 0 if a
 *                           measurement was emitted, < 0 otherwise. *rearmed
 *                           goes false if the beacon must be re-armed (on-demand
 *                           path only). NO distance computation (done off-board).
 * Collection consumes no airtime: the N links' procedures run in the
 * background, the per-beacon rate = procedure_interval x connection interval
 * (measurements not collected in time: overwritten, not accumulated). */
/* Timestamped IQ dump to the data UART (ON by default, disabled by the UART
 * command IQOFF / re-enabled by IQON, line format documented in GUIDE.md). */
extern bool cs_iq_dump;

int cs_enable_beacon(int i);
int cs_collect_beacon(int i, bool *rearmed);

#endif /* CS_RANGING_H */
```

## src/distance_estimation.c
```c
#include <zephyr/logging/log.h>
LOG_MODULE_DECLARE(app_main, LOG_LEVEL_INF);

#include <zephyr/bluetooth/cs.h>
#include <bluetooth/services/ras.h>
#include <zephyr/bluetooth/hci_types.h>
#include "ble_protocol_data.h"
#include "beacon.h"
#include <math.h>

#define MAX_NUM_IQ_SAMPLES (256 * CONFIG_BT_RAS_MAX_ANTENNA_PATHS)
#define DISTANCE_FILTER_LEN 8

#define CS_FREQUENCY_MHZ(ch)   (2402u + 1u * (ch))
#define SPEED_OF_LIGHT_M_PER_S 299792458.0f
#define PI                     3.14159265358979323846f

struct iq_sample_and_channel {
	bool failed;
	uint8_t channel;
	uint8_t antenna_permutation;
	struct bt_le_cs_iq_sample local_iq_sample;
	struct bt_le_cs_iq_sample peer_iq_sample;
};

static struct iq_sample_and_channel iq_sample_channel_data[MAX_NUM_IQ_SAMPLES];

/* Un filtre glissant PAR beacon : un filtre global mélangerait les
 * distances mesurées vers des réflecteurs différents. */
static float distance_filter[MAX_BEACONS][DISTANCE_FILTER_LEN];
static uint8_t distance_filter_idx[MAX_BEACONS];
static uint8_t distance_filter_count[MAX_BEACONS];

static float filtered_distance(uint8_t beacon_idx, float new_sample)
{
	if (beacon_idx >= MAX_BEACONS) {
		return -1.0f;
	}
	if (new_sample <= 0.0f || new_sample > 50.0f) {
		return -1.0f;
	}
	distance_filter[beacon_idx][distance_filter_idx[beacon_idx]] = new_sample;
	distance_filter_idx[beacon_idx] =
		(distance_filter_idx[beacon_idx] + 1) % DISTANCE_FILTER_LEN;
	if (distance_filter_count[beacon_idx] < DISTANCE_FILTER_LEN) {
		distance_filter_count[beacon_idx]++;
	}
	float sum = 0.0f;
	for (uint8_t i = 0; i < distance_filter_count[beacon_idx]; i++) {
		sum += distance_filter[beacon_idx][i];
	}
	return sum / distance_filter_count[beacon_idx];
}

struct processing_context {
	uint16_t iq_sample_channel_data_index;
	uint8_t n_ap;
	enum bt_conn_le_cs_role role;
};

static void process_tone_info_data(struct processing_context *context,
			      struct bt_hci_le_cs_step_data_tone_info local_tone_info[],
			      struct bt_hci_le_cs_step_data_tone_info peer_tone_info[],
			      uint8_t channel, uint8_t antenna_permutation_index)
{
	for (uint8_t i = 0; i < (context->n_ap + 1); i++) {
		if (local_tone_info[i].extension_indicator != BT_HCI_LE_CS_NOT_TONE_EXT_SLOT ||
		    peer_tone_info[i].extension_indicator != BT_HCI_LE_CS_NOT_TONE_EXT_SLOT) {
			continue;
		}

		if (context->iq_sample_channel_data_index >= MAX_NUM_IQ_SAMPLES) {
			LOG_WRN("Too many IQ samples");
			return;
		}

		struct iq_sample_and_channel *entry =
			&iq_sample_channel_data[context->iq_sample_channel_data_index];

		entry->channel = channel;
		entry->antenna_permutation = antenna_permutation_index;
		entry->local_iq_sample =
			bt_le_cs_parse_pct(local_tone_info[i].phase_correction_term);
		entry->peer_iq_sample =
			bt_le_cs_parse_pct(peer_tone_info[i].phase_correction_term);

		entry->failed =
			(local_tone_info[i].quality_indicator == BT_HCI_LE_CS_TONE_QUALITY_LOW ||
			 local_tone_info[i].quality_indicator == BT_HCI_LE_CS_TONE_QUALITY_UNAVAILABLE ||
			 peer_tone_info[i].quality_indicator == BT_HCI_LE_CS_TONE_QUALITY_LOW ||
			 peer_tone_info[i].quality_indicator == BT_HCI_LE_CS_TONE_QUALITY_UNAVAILABLE);

		context->iq_sample_channel_data_index++;
	}
}

static bool process_step_data(struct bt_le_cs_subevent_step *local_step,
			      struct bt_le_cs_subevent_step *peer_step, void *user_data)
{
	struct processing_context *context = (struct processing_context *)user_data;

	if (local_step->mode == BT_HCI_OP_LE_CS_MAIN_MODE_2 ||
	    local_step->mode == BT_HCI_OP_LE_CS_MAIN_MODE_3) {

		struct bt_hci_le_cs_step_data_mode_2 *local_step_data =
			(struct bt_hci_le_cs_step_data_mode_2 *)local_step->data;
		struct bt_hci_le_cs_step_data_mode_2 *peer_step_data =
			(struct bt_hci_le_cs_step_data_mode_2 *)peer_step->data;

		process_tone_info_data(context, local_step_data->tone_info,
				       peer_step_data->tone_info, local_step->channel,
				       local_step_data->antenna_permutation_index);
	}

	return true;
}

static void calc_complex_product(int32_t z_a_real, int32_t z_a_imag, int32_t z_b_real,
				 int32_t z_b_imag, int32_t *z_out_real, int32_t *z_out_imag)
{
	*z_out_real = z_a_real * z_b_real - z_a_imag * z_b_imag;
	*z_out_imag = z_a_real * z_b_imag + z_a_imag * z_b_real;
}

static float linear_regression(float *x_values, float *y_values, uint16_t n_samples)
{
	if (n_samples == 0) {
		return 0.0f;
	}

	float y_mean = 0.0f;
	float x_mean = 0.0f;

	for (uint16_t i = 0; i < n_samples; i++) {
		y_mean += (y_values[i] - y_mean) / (i + 1);
		x_mean += (x_values[i] - x_mean) / (i + 1);
	}

	float b_est_upper = 0.0f;
	float b_est_lower = 0.0f;

	for (uint16_t i = 0; i < n_samples; i++) {
		b_est_upper += (x_values[i] - x_mean) * (y_values[i] - y_mean);
		b_est_lower += (x_values[i] - x_mean) * (x_values[i] - x_mean);
	}

	return b_est_upper / b_est_lower;
}

static void bubblesort_2(float *array1, float *array2, uint16_t len)
{
	for (uint16_t i = 0; i < len - 1; i++) {
		for (uint16_t j = 0; j < len - i - 1; j++) {
			if (array1[j] > array1[j + 1]) {
				float temp1 = array1[j];
				array1[j] = array1[j + 1];
				array1[j + 1] = temp1;

				float temp2 = array2[j];
				array2[j] = array2[j + 1];
				array2[j + 1] = temp2;
			}
		}
	}
}

static float estimate_distance_using_phase_slope(struct iq_sample_and_channel *data, uint16_t len)
{
	int32_t combined_i, combined_q;
	uint16_t num_angles = 0;
	static float theta[MAX_NUM_IQ_SAMPLES];
	static float frequencies[MAX_NUM_IQ_SAMPLES];

	for (uint16_t i = 0; i < len; i++) {
		if (!data[i].failed) {
			calc_complex_product(data[i].local_iq_sample.i, data[i].local_iq_sample.q,
					     data[i].peer_iq_sample.i, data[i].peer_iq_sample.q,
					     &combined_i, &combined_q);

			theta[num_angles] = atan2f((float)combined_q, (float)combined_i);
			frequencies[num_angles] = (float)CS_FREQUENCY_MHZ(data[i].channel);
			num_angles++;
		}
	}

	if (num_angles < 2) {
		return 0.0f;
	}

	bubblesort_2(frequencies, theta, num_angles);

	for (uint16_t i = 1; i < num_angles; i++) {
		float diff = theta[i] - theta[i - 1];
		if (diff > PI) {
			for (uint16_t j = i; j < num_angles; j++) {
				theta[j] -= 2.0f * PI;
			}
		} else if (diff < -PI) {
			for (uint16_t j = i; j < num_angles; j++) {
				theta[j] += 2.0f * PI;
			}
		}
	}

	float phase_slope = linear_regression(frequencies, theta, num_angles);
	float distance = -phase_slope * (SPEED_OF_LIGHT_M_PER_S / (4 * PI));

	return distance / 1e6f; // Convert to meters
}

float estimate_distance(struct net_buf_simple *local_steps, struct net_buf_simple *peer_steps,
			uint8_t n_ap, enum bt_conn_le_cs_role role, uint8_t beacon_idx)
{
	struct processing_context context = {
		.iq_sample_channel_data_index = 0,
		.n_ap = n_ap,
		.role = role,
	};
	static struct iq_sample_packet out_samples[MAX_NUM_IQ_SAMPLES];
	uint16_t valid_sample_count = 0;

	memset(iq_sample_channel_data, 0, sizeof(iq_sample_channel_data));

	bt_ras_rreq_rd_subevent_data_parse(peer_steps, local_steps, context.role, NULL,
					   NULL, process_step_data, &context);

	float distance_m = estimate_distance_using_phase_slope(iq_sample_channel_data,
		context.iq_sample_channel_data_index);

	float smoothed_m = filtered_distance(beacon_idx, distance_m);
	if (smoothed_m > 0.0f) {
		LOG_INF("Beacon[%u] distance: %.2f m (raw: %.2f m)",
			beacon_idx, (double)smoothed_m, (double)distance_m);
	} else {
		LOG_WRN("Beacon[%u] distance hors plage (raw: %.2f m)",
			beacon_idx, (double)distance_m);
	}

	for (uint16_t i = 0; i < context.iq_sample_channel_data_index; i++) {
		if (iq_sample_channel_data[i].failed) {
			continue;
		}

		out_samples[valid_sample_count].beacon_idx = beacon_idx;
		out_samples[valid_sample_count].channel = iq_sample_channel_data[i].channel;
		out_samples[valid_sample_count].antenna_index = iq_sample_channel_data[i].antenna_permutation;
		out_samples[valid_sample_count].local_i = iq_sample_channel_data[i].local_iq_sample.i;
		out_samples[valid_sample_count].local_q = iq_sample_channel_data[i].local_iq_sample.q;
		out_samples[valid_sample_count].peer_i = iq_sample_channel_data[i].peer_iq_sample.i;
		out_samples[valid_sample_count].peer_q = iq_sample_channel_data[i].peer_iq_sample.q;
		out_samples[valid_sample_count].phase_distance_m = distance_m;

		valid_sample_count++;
	}

	if (valid_sample_count > 0) {
		ble_protocol_data_send_batch(out_samples, valid_sample_count);
	}

	return smoothed_m;
}
```

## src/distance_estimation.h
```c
/*
 * Copyright (c) 2024 Nordic Semiconductor ASA
 *
 * SPDX-License-Identifier: LicenseRef-Nordic-5-Clause
 */

#include <stdint.h>
#include <zephyr/bluetooth/cs.h>

/* Calcule la distance (phase slope) à partir des steps locaux et distants,
 * applique le filtre glissant propre au beacon `beacon_idx`, et exporte les
 * échantillons IQ via ble_protocol_data.
 * Retourne la distance filtrée en mètres, ou -1.0f si hors plage/échec. */
float estimate_distance(struct net_buf_simple *local_steps, struct net_buf_simple *peer_steps,
			uint8_t n_ap, enum bt_conn_le_cs_role role, uint8_t beacon_idx);
```

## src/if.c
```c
#include "if.h"
#include <string.h>
#include <zephyr/kernel.h>
#include <zephyr/drivers/uart.h>
#include <zephyr/logging/log.h>

LOG_MODULE_DECLARE(app_main, LOG_LEVEL_INF);

/* 1 = uart30 (VCOM Serial Port 0, bench PC via USB — cs_console.py)
 * 0 = uart21 (P1.08/P1.09, extension header — drone companion in flight)
 * See the full mapping in boards/nrf54l15dk_nrf54l15_cpuapp.overlay. */
#define IF_UART_ON_VCOM 1

#if IF_UART_ON_VCOM
#define UART_NODE DT_NODELABEL(uart30)
#else
#define UART_NODE DT_NODELABEL(uart21)
#endif

static const struct device *uart_dev = DEVICE_DT_GET(UART_NODE);

/* ── RX: line commands (scheduler) ───────────────────────────────────────────
 * The ISR accumulates until '\n' then delegates parsing to the system
 * workqueue (thread context: the user handler may take mutexes/log). A line
 * arriving while the previous one is being processed overwrites it — of no
 * consequence for occasional configuration commands. */
#define IF_LINE_MAX 64

static if_line_cb_t line_cb;
static char         rx_acc[IF_LINE_MAX];
static size_t       rx_len;
static char         pending_line[IF_LINE_MAX];
static struct k_work line_work;

static void line_work_handler(struct k_work *work)
{
	if (line_cb) {
		line_cb(pending_line);
	}
}

static void uart_isr(const struct device *dev, void *user_data)
{
	uint8_t c;

	while (uart_irq_update(dev) && uart_irq_rx_ready(dev)) {
		while (uart_fifo_read(dev, &c, 1) == 1) {
			if (c == '\n' || c == '\r') {
				if (rx_len > 0) {
					memcpy(pending_line, rx_acc, rx_len);
					pending_line[rx_len] = '\0';
					rx_len = 0;
					k_work_submit(&line_work);
				}
			} else if (rx_len < IF_LINE_MAX - 1) {
				rx_acc[rx_len++] = (char)c;
			} else {
				rx_len = 0; /* line too long: discard */
			}
		}
	}
}

int if_initialisation(void)
{
	if (!device_is_ready(uart_dev)) {
		return -1;
	}
	return 0;
}

void if_set_line_cb(if_line_cb_t cb)
{
	line_cb = cb;
	k_work_init(&line_work, line_work_handler);
	uart_irq_callback_user_data_set(uart_dev, uart_isr, NULL);
	uart_irq_rx_enable(uart_dev);
}

void if_send(uint8_t *buffer, size_t len)
{
	for (size_t i = 0; i < len; i++) {
		uart_poll_out(uart_dev, buffer[i]);
	}
}
```

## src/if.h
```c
#ifndef IF_H_
#define IF_H_

#include <stddef.h>
#include <stdint.h>

typedef void (*if_line_cb_t)(const char *line);

int  if_initialisation(void);
void if_send(uint8_t *buffer, size_t len);
/* Enables line-by-line UART reception ('\n' or '\r') and registers the
 * handler, called in workqueue context (mutex/log allowed). */
void if_set_line_cb(if_line_cb_t cb);

#endif /* IF_H_ */
```
